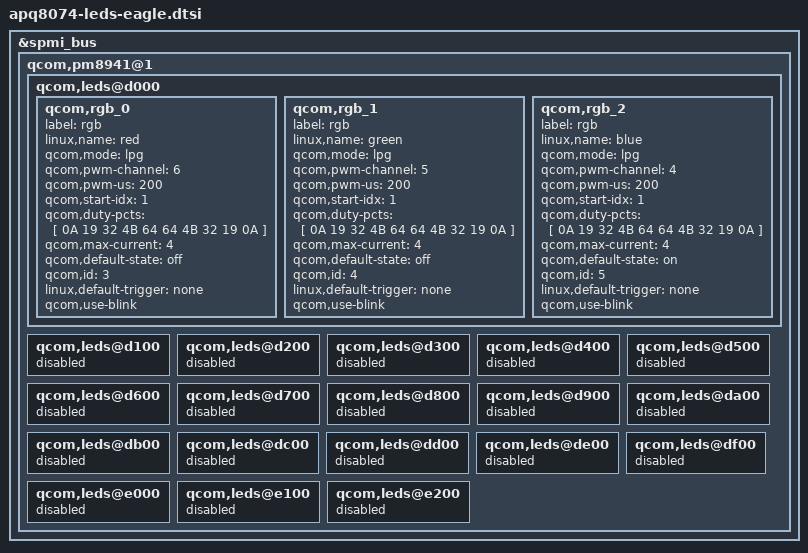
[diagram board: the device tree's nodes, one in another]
/*
 * Copyright (c) 2012-2013, 2015, The Linux Foundation. All rights reserved.
 *
 * This program is free software; you can redistribute it and/or modify
 * it under the terms of the GNU General Public License version 2 and
 * only version 2 as published by the Free Software Foundation.
 *
 * This program is distributed in the hope that it will be useful,
 * but WITHOUT ANY WARRANTY; without even the implied warranty of
 * MERCHANTABILITY or FITNESS FOR A PARTICULAR PURPOSE.  See the
 * GNU General Public License for more details.
 */

&spmi_bus {
	qcom,pm8941@1 {
		qcom,leds@d000 {
			status = "okay";
			qcom,rgb_0 {
				label = "rgb";
				linux,name = "red";
				qcom,mode = "lpg";
				qcom,pwm-channel = <6>;
				qcom,pwm-us = <200>;
				qcom,start-idx = <1>;
				qcom,duty-pcts = [
					0A 19 32 4B 64
					64 4B 32 19 0A
					];
				qcom,max-current = <4>;
				qcom,default-state = "off";
				qcom,id = <3>;
				linux,default-trigger = "none";
				qcom,use-blink;
			};

			qcom,rgb_1 {
				label = "rgb";
				linux,name = "green";
				qcom,mode = "lpg";
				qcom,pwm-channel = <5>;
				qcom,pwm-us = <200>;
                                qcom,start-idx = <1>;
                                qcom,duty-pcts = [
                                        0A 19 32 4B 64
                                        64 4B 32 19 0A
                                        ];
				qcom,max-current = <4>;
				qcom,default-state = "off";
				qcom,id = <4>;
				linux,default-trigger = "none";
				qcom,use-blink;
			};

			qcom,rgb_2 {
				label = "rgb";
				linux,name = "blue";
				qcom,mode = "lpg";
				qcom,pwm-channel = <4>;
				qcom,pwm-us = <200>;
                                qcom,start-idx = <1>;
                                qcom,duty-pcts = [
                                        0A 19 32 4B 64
                                        64 4B 32 19 0A
                                        ];
				qcom,max-current = <4>;
				qcom,default-state = "on";
				qcom,id = <5>;
				linux,default-trigger = "none";
				qcom,use-blink;
			};
		};

		qcom,leds@d100 {
			status = "disabled";
		};

		qcom,leds@d200 {
			status = "disabled";
		};

		qcom,leds@d300 {
			status = "disabled";
		};

		qcom,leds@d400 {
			status = "disabled";
		};

		qcom,leds@d500 {
			status = "disabled";
		};

		qcom,leds@d600 {
			status = "disabled";
		};

		qcom,leds@d700 {
			status = "disabled";
		};

		qcom,leds@d800 {
			status = "disabled";
		};

		qcom,leds@d900 {
			status = "disabled";
		};

		qcom,leds@da00 {
			status = "disabled";
		};

		qcom,leds@db00 {
			status = "disabled";
		};

		qcom,leds@dc00 {
			status = "disabled";
		};

		qcom,leds@dd00 {
			status = "disabled";
		};

		qcom,leds@de00 {
			status = "disabled";
		};

		qcom,leds@df00 {
			status = "disabled";
		};

		qcom,leds@e000 {
			status = "disabled";
		};

		qcom,leds@e100 {
			status = "disabled";
		};

		qcom,leds@e200 {
			status = "disabled";
		};
	};
};

